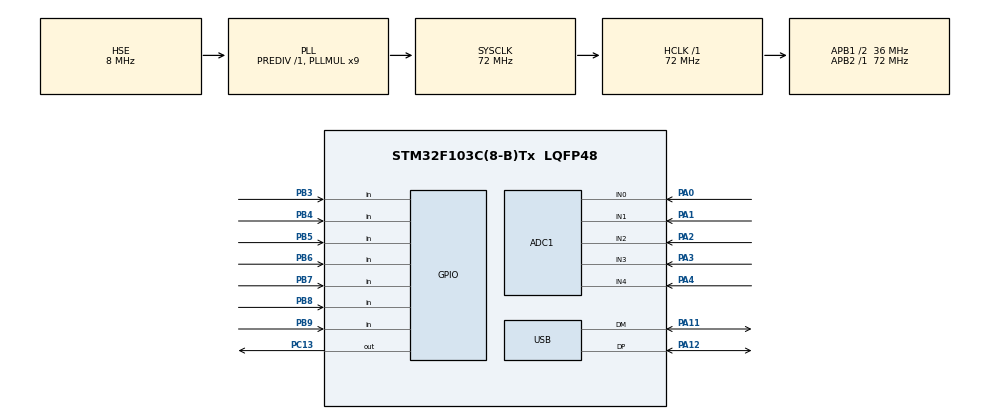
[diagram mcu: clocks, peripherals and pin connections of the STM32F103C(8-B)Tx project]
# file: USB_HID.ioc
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ADC1.Channel-10\#ChannelRegularConversion=ADC_CHANNEL_0
ADC1.Channel-11\#ChannelRegularConversion=ADC_CHANNEL_0
ADC1.Channel-4\#ChannelRegularConversion=ADC_CHANNEL_0
ADC1.Channel-8\#ChannelRegularConversion=ADC_CHANNEL_0
ADC1.Channel-9\#ChannelRegularConversion=ADC_CHANNEL_0
ADC1.ContinuousConvMode=ENABLE
ADC1.DataAlign=ADC_DATAALIGN_RIGHT
ADC1.NbrOfConversion=5
ADC1.NbrOfConversionFlag=1
ADC1.Rank-10\#ChannelRegularConversion=4
ADC1.Rank-11\#ChannelRegularConversion=5
ADC1.Rank-4\#ChannelRegularConversion=1
ADC1.Rank-8\#ChannelRegularConversion=2
ADC1.Rank-9\#ChannelRegularConversion=3
ADC1.SamplingTime-10\#ChannelRegularConversion=ADC_SAMPLETIME_1CYCLE_5
ADC1.SamplingTime-11\#ChannelRegularConversion=ADC_SAMPLETIME_1CYCLE_5
ADC1.SamplingTime-4\#ChannelRegularConversion=ADC_SAMPLETIME_1CYCLE_5
ADC1.SamplingTime-8\#ChannelRegularConversion=ADC_SAMPLETIME_1CYCLE_5
ADC1.SamplingTime-9\#ChannelRegularConversion=ADC_SAMPLETIME_1CYCLE_5
ADC1.master=1
Dma.ADC1.0.Direction=DMA_PERIPH_TO_MEMORY
Dma.ADC1.0.Instance=DMA1_Channel1
Dma.ADC1.0.MemDataAlignment=DMA_MDATAALIGN_HALFWORD
Dma.ADC1.0.MemInc=DMA_MINC_ENABLE
Dma.ADC1.0.Mode=DMA_CIRCULAR
Dma.ADC1.0.PeriphDataAlignment=DMA_PDATAALIGN_HALFWORD
Dma.ADC1.0.PeriphInc=DMA_PINC_DISABLE
Dma.ADC1.0.Priority=DMA_PRIORITY_HIGH
Dma.Request0=ADC1
Mcu.Family=STM32F1
Mcu.Name=STM32F103C(8-B)Tx
Mcu.Package=LQFP48
NVIC.DMA1_Channel1_IRQn=true\:0\:0\:false\:false\:true\:false\:true
NVIC.PriorityGroup=NVIC_PRIORITYGROUP_4
NVIC.USB_LP_CAN1_RX0_IRQn=true\:0\:0\:false\:false\:true\:false\:true
PA0-WKUP.Signal=ADCx_IN0
PA1.Signal=ADCx_IN1
PA11.Mode=Device
PA11.Signal=USB_DM
PA12.Mode=Device
PA12.Signal=USB_DP
PA13.Mode=Serial_Wire
PA13.Signal=SYS_JTMS-SWDIO
PA14.Mode=Serial_Wire
PA14.Signal=SYS_JTCK-SWCLK
PA2.Signal=ADCx_IN2
PA3.Signal=ADCx_IN3
PA4.Signal=ADCx_IN4
PB3.Signal=GPIO_Input
PB4.Signal=GPIO_Input
PB5.Signal=GPIO_Input
PB6.Signal=GPIO_Input
PB7.Signal=GPIO_Input
PB8.Signal=GPIO_Input
PB9.Signal=GPIO_Input
PC13-TAMPER-RTC.Signal=GPIO_Output
PC14-OSC32_IN.Mode=LSE-External-Oscillator
PC14-OSC32_IN.Signal=RCC_OSC32_IN
PC15-OSC32_OUT.Mode=LSE-External-Oscillator
PC15-OSC32_OUT.Signal=RCC_OSC32_OUT
PD0-OSC_IN.Mode=HSE-External-Oscillator
PD0-OSC_IN.Signal=RCC_OSC_IN
PD1-OSC_OUT.Mode=HSE-External-Oscillator
PD1-OSC_OUT.Signal=RCC_OSC_OUT
ProjectManager.HeapSize=0x200
ProjectManager.StackSize=0x400
ProjectManager.TargetToolchain=MDK-ARM V5
RCC.ADCPresc=RCC_ADCPCLK2_DIV6
RCC.AHBFreq_Value=72000000
RCC.APB1CLKDivider=RCC_HCLK_DIV2
RCC.APB1Freq_Value=36000000
RCC.APB1TimFreq_Value=72000000
RCC.APB2Freq_Value=72000000
RCC.APB2TimFreq_Value=72000000
RCC.HCLKFreq_Value=72000000
RCC.PLLMUL=RCC_PLL_MUL9
RCC.SYSCLKFreq_VALUE=72000000
RCC.SYSCLKSource=RCC_SYSCLKSOURCE_PLLCLK
RCC.USBFreq_Value=48000000
RCC.USBPrescaler=RCC_USBCLKSOURCE_PLL_DIV1_5
SH.ADCx_IN0.0=ADC1_IN0,IN0
SH.ADCx_IN1.0=ADC1_IN1,IN1
SH.ADCx_IN2.0=ADC1_IN2,IN2
SH.ADCx_IN3.0=ADC1_IN3,IN3
SH.ADCx_IN4.0=ADC1_IN4,IN4
USB.low_power_enable=DISABLE
USB_DEVICE.CLASS_NAME_FS=CUSTOM_HID
USB_DEVICE.USBD_CUSTOMHID_OUTREPORT_BUF_SIZE=64
USB_DEVICE.USBD_CUSTOM_HID_REPORT_DESC_SIZE=61
USB_DEVICE.VirtualMode=CustomHid
USB_DEVICE.VirtualModeFS=Custom_Hid_FS
VP_TIM1_VS_ClockSourceINT.Mode=Internal
VP_USB_DEVICE_VS_USB_DEVICE_CUSTOM_HID_FS.Mode=CUSTOM_HID_FS
board=custom

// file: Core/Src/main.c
/* USER CODE BEGIN Header */
/**
  ******************************************************************************
  * @file           : main.c
  * @brief          : Main program body
  ******************************************************************************
  * @attention
  *
  * <h2><center>&copy; Copyright (c) 2021 STMicroelectronics.
  * All rights reserved.</center></h2>
  *
  * This software component is licensed by ST under Ultimate Liberty license
  * SLA0044, the "License"; You may not use this file except in compliance with
  * the License. You may obtain a copy of the License at:
  *                             www.st.com/SLA0044
  *
  ******************************************************************************
  */
/* USER CODE END Header */
#include "main.h"
#include "usb_device.h"

ADC_HandleTypeDef hadc1;
DMA_HandleTypeDef hdma_adc1;

TIM_HandleTypeDef htim1;

void SystemClock_Config(void);
static void MX_GPIO_Init(void);
static void MX_TIM1_Init(void);
static void MX_DMA_Init(void);
static void MX_ADC1_Init(void);

int main(void)
{

  /* MCU Configuration--------------------------------------------------------*/

  /* Reset of all peripherals, Initializes the Flash interface and the Systick. */
  HAL_Init();

  /* Configure the system clock */
  SystemClock_Config();

  /* Initialize all configured peripherals */
  MX_GPIO_Init();
  MX_USB_DEVICE_Init();
  MX_TIM1_Init();
  MX_DMA_Init();
  MX_ADC1_Init();
  /* USER CODE BEGIN 2 */
uint8_t send_buf[8] = {0};
send_buf[2] |= Keyboard_w;
int i=0;
  /* USER CODE END 2 */

  /* Infinite loop */
  /* USER CODE BEGIN WHILE */
	//	HAL_GPIO_WritePin(GPIOB, GPIO_PIN_3, GPIO_PIN_SET);
	GPIO_PinState bitstatus;
  while (1)
  {
    /* USER CODE END WHILE */

  }
}

void SystemClock_Config(void)
{
  RCC_OscInitTypeDef RCC_OscInitStruct = {0};
  RCC_ClkInitTypeDef RCC_ClkInitStruct = {0};
  RCC_PeriphCLKInitTypeDef PeriphClkInit = {0};

  /** Initializes the RCC Oscillators according to the specified parameters
  * in the RCC_OscInitTypeDef structure.
  */
  RCC_OscInitStruct.OscillatorType = RCC_OSCILLATORTYPE_HSE;
  RCC_OscInitStruct.HSEState = RCC_HSE_ON;
  RCC_OscInitStruct.HSEPredivValue = RCC_HSE_PREDIV_DIV1;
  RCC_OscInitStruct.HSIState = RCC_HSI_ON;
  RCC_OscInitStruct.PLL.PLLState = RCC_PLL_ON;
  RCC_OscInitStruct.PLL.PLLSource = RCC_PLLSOURCE_HSE;
  RCC_OscInitStruct.PLL.PLLMUL = RCC_PLL_MUL9;
  if (HAL_RCC_OscConfig(&RCC_OscInitStruct) != HAL_OK)
  {
    Error_Handler();
  }
  /** Initializes the CPU, AHB and APB buses clocks
  */
  RCC_ClkInitStruct.ClockType = RCC_CLOCKTYPE_HCLK|RCC_CLOCKTYPE_SYSCLK
                              |RCC_CLOCKTYPE_PCLK1|RCC_CLOCKTYPE_PCLK2;
  RCC_ClkInitStruct.SYSCLKSource = RCC_SYSCLKSOURCE_PLLCLK;
  RCC_ClkInitStruct.AHBCLKDivider = RCC_SYSCLK_DIV1;
  RCC_ClkInitStruct.APB1CLKDivider = RCC_HCLK_DIV2;
  RCC_ClkInitStruct.APB2CLKDivider = RCC_HCLK_DIV1;

  if (HAL_RCC_ClockConfig(&RCC_ClkInitStruct, FLASH_LATENCY_2) != HAL_OK)
  {
    Error_Handler();
  }
  PeriphClkInit.PeriphClockSelection = RCC_PERIPHCLK_ADC|RCC_PERIPHCLK_USB;
  PeriphClkInit.AdcClockSelection = RCC_ADCPCLK2_DIV6;
  PeriphClkInit.UsbClockSelection = RCC_USBCLKSOURCE_PLL_DIV1_5;
  if (HAL_RCCEx_PeriphCLKConfig(&PeriphClkInit) != HAL_OK)
  {
    Error_Handler();
  }
}

static void MX_ADC1_Init(void)
{

  ADC_ChannelConfTypeDef sConfig = {0};

  /** Common config
  */
  hadc1.Instance = ADC1;
  hadc1.Init.ScanConvMode = ADC_SCAN_ENABLE;
  hadc1.Init.ContinuousConvMode = ENABLE;
  hadc1.Init.DiscontinuousConvMode = DISABLE;
  hadc1.Init.ExternalTrigConv = ADC_SOFTWARE_START;
  hadc1.Init.DataAlign = ADC_DATAALIGN_RIGHT;
  hadc1.Init.NbrOfConversion = 5;
  if (HAL_ADC_Init(&hadc1) != HAL_OK)
  {
    Error_Handler();
  }
  /** Configure Regular Channel
  */
  sConfig.Channel = ADC_CHANNEL_0;
  sConfig.Rank = ADC_REGULAR_RANK_1;
  sConfig.SamplingTime = ADC_SAMPLETIME_1CYCLE_5;
  if (HAL_ADC_ConfigChannel(&hadc1, &sConfig) != HAL_OK)
  {
    Error_Handler();
  }
  /** Configure Regular Channel
  */
  sConfig.Rank = ADC_REGULAR_RANK_2;
  if (HAL_ADC_ConfigChannel(&hadc1, &sConfig) != HAL_OK)
  {
    Error_Handler();
  }
  /** Configure Regular Channel
  */
  sConfig.Rank = ADC_REGULAR_RANK_3;
  if (HAL_ADC_ConfigChannel(&hadc1, &sConfig) != HAL_OK)
  {
    Error_Handler();
  }
  /** Configure Regular Channel
  */
  sConfig.Rank = ADC_REGULAR_RANK_4;
  if (HAL_ADC_ConfigChannel(&hadc1, &sConfig) != HAL_OK)
  {
    Error_Handler();
  }
  /** Configure Regular Channel
  */
  sConfig.Rank = ADC_REGULAR_RANK_5;
  if (HAL_ADC_ConfigChannel(&hadc1, &sConfig) != HAL_OK)
  {
    Error_Handler();
  }

}

static void MX_TIM1_Init(void)
{

  TIM_ClockConfigTypeDef sClockSourceConfig = {0};
  TIM_MasterConfigTypeDef sMasterConfig = {0};

  htim1.Instance = TIM1;
  htim1.Init.Prescaler = 0;
  htim1.Init.CounterMode = TIM_COUNTERMODE_UP;
  htim1.Init.Period = 65535;
  htim1.Init.ClockDivision = TIM_CLOCKDIVISION_DIV1;
  htim1.Init.RepetitionCounter = 0;
  htim1.Init.AutoReloadPreload = TIM_AUTORELOAD_PRELOAD_DISABLE;
  if (HAL_TIM_Base_Init(&htim1) != HAL_OK)
  {
    Error_Handler();
  }
  sClockSourceConfig.ClockSource = TIM_CLOCKSOURCE_INTERNAL;
  if (HAL_TIM_ConfigClockSource(&htim1, &sClockSourceConfig) != HAL_OK)
  {
    Error_Handler();
  }
  sMasterConfig.MasterOutputTrigger = TIM_TRGO_RESET;
  sMasterConfig.MasterSlaveMode = TIM_MASTERSLAVEMODE_DISABLE;
  if (HAL_TIMEx_MasterConfigSynchronization(&htim1, &sMasterConfig) != HAL_OK)
  {
    Error_Handler();
  }

}

static void MX_DMA_Init(void)
{

  /* DMA controller clock enable */
  __HAL_RCC_DMA1_CLK_ENABLE();

  /* DMA interrupt init */
  /* DMA1_Channel1_IRQn interrupt configuration */
  HAL_NVIC_SetPriority(DMA1_Channel1_IRQn, 0, 0);
  HAL_NVIC_EnableIRQ(DMA1_Channel1_IRQn);

}

static void MX_GPIO_Init(void)
{
  GPIO_InitTypeDef GPIO_InitStruct = {0};

  /* GPIO Ports Clock Enable */
  __HAL_RCC_GPIOC_CLK_ENABLE();
  __HAL_RCC_GPIOD_CLK_ENABLE();
  __HAL_RCC_GPIOA_CLK_ENABLE();
  __HAL_RCC_GPIOB_CLK_ENABLE();

  /*Configure GPIO pin Output Level */
  HAL_GPIO_WritePin(GPIOC, GPIO_PIN_13, GPIO_PIN_RESET);

  /*Configure GPIO pin : PC13 */
  GPIO_InitStruct.Pin = GPIO_PIN_13;
  GPIO_InitStruct.Mode = GPIO_MODE_OUTPUT_PP;
  GPIO_InitStruct.Pull = GPIO_NOPULL;
  GPIO_InitStruct.Speed = GPIO_SPEED_FREQ_LOW;
  HAL_GPIO_Init(GPIOC, &GPIO_InitStruct);

  /*Configure GPIO pins : PB3 PB4 PB5 PB6
                           PB7 PB8 PB9 */
  GPIO_InitStruct.Pin = GPIO_PIN_3|GPIO_PIN_4|GPIO_PIN_5|GPIO_PIN_6
                          |GPIO_PIN_7|GPIO_PIN_8|GPIO_PIN_9;
  GPIO_InitStruct.Mode = GPIO_MODE_INPUT;
  GPIO_InitStruct.Pull = GPIO_NOPULL;
  HAL_GPIO_Init(GPIOB, &GPIO_InitStruct);

}

void Error_Handler(void)
{
  __disable_irq();
  while (1)
  {
  }
}

/************************ (C) COPYRIGHT STMicroelectronics *****END OF FILE****/
